# SERDES_10G0 register map
Vendor: Texas Instruments
Registers are 32-bit, access per field, reset 0x0 unless marked. A register's access mark holds for its fields unless they carry their own. Offsets are as the file gives them; [hi:lo] are bit positions; {n}, {i} and the like mark numbered series.

## SERDES_10G0 (part 2 of 8)
0x00 CMN_PID_TYPE ro reset 0x7364 — Product type ID register
  [15:0] CMN_PID_TYPE_15_0 — Product type : This field contains the ASCII codes that represent the product type sd for SerDes.
0x04 CMN_PID_NUM ro reset 0x8010000 — Product number ID register
  [31:16] CMN_PID_NUM_15_0 — Product number : This field contains the binary coded decimal numbers that represent the product number.
0x08 CMN_PID_REV ro reset 0x120 — Product revision ID register
  [15:0] CMN_PID_REV_15_0 — Product revision : This field contains the binary coded decimal numbers that represent the product revision.
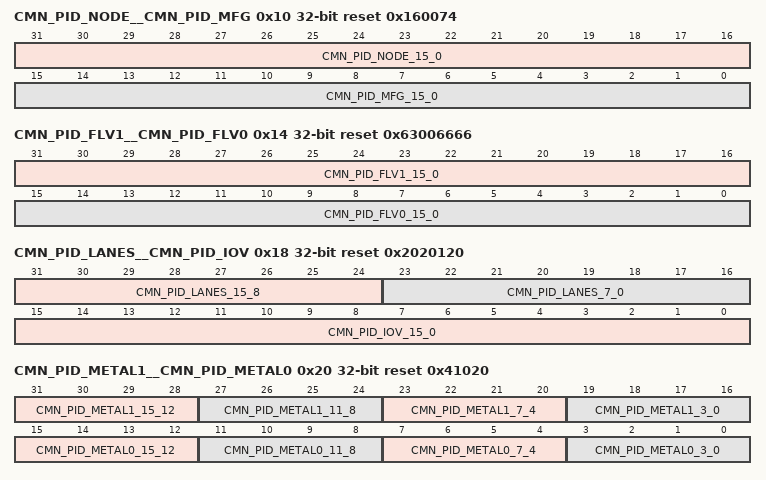
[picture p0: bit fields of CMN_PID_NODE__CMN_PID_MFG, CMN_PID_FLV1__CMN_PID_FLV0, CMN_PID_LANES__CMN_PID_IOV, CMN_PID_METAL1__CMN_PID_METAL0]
0x10 CMN_PID_NODE__CMN_PID_MFG ro reset 0x160074 — Product technology manufacturer ID register
  [31:16] CMN_PID_NODE_15_0 — Product technology process node : This field contains the binary coded decimal numbers that represent the product technology node
  [15:0] CMN_PID_MFG_15_0 — Product technology manufacturer : This field contains the ASCII codes that represent the product technology manufacturer t for TSMC.
0x14 CMN_PID_FLV1__CMN_PID_FLV0 ro reset 0x63006666 — Product technology process flavor ID register 0
  [31:16] CMN_PID_FLV1_15_0 — Product technology flavor : This field contains the ASCII codes that represent the second two characters of the product technology flavor.
  [15:0] CMN_PID_FLV0_15_0 — Product technology flavor : This field contains the ASCII codes that represent the first two characters of the product technology flavor.
0x18 CMN_PID_LANES__CMN_PID_IOV ro reset 0x2020120 — Product I/O voltage ID register
  [31:24] CMN_PID_LANES_15_8 — Product SerDes lanes left of common : This field contains the binary coded decimal numbers that represent the number of lanes implemented in this SerDes product on the left side of the common module.
  [23:16] CMN_PID_LANES_7_0 — Product SerDes lanes right of common : This field contains the binary coded decimal numbers that represent the number of lanes implemented in this SerDes product on the right side of the common module.
  [15:0] CMN_PID_IOV_15_0 — Product I/O voltage : This field contains the binary coded decimal numbers that represent the product I/O voltage.
0x20 CMN_PID_METAL1__CMN_PID_METAL0 ro reset 0x41020 — Product metal layers ID register 0
  [31:28] CMN_PID_METAL1_15_12 — Reserved
  [27:24] CMN_PID_METAL1_11_8 — Reserved
  [23:20] CMN_PID_METAL1_7_4 — Product xy metal layers : This field contains the binary coded decimal number that represent the number of xy metal layers used for this product.
  [19:16] CMN_PID_METAL1_3_0 — Product xe metal layers : This field contains the binary coded decimal number that represent the number of xe metal layers used for this product.
  [15:12] CMN_PID_METAL0_15_12 — Product xd metal layers : This field contains the binary coded decimal number that represent the number of xd metal layers used for this product.
  [11:8] CMN_PID_METAL0_11_8 — Product xc metal layers : This field contains the binary coded decimal number that represent the number of xc metal layers used for this product.
  [7:4] CMN_PID_METAL0_7_4 — Product xa metal layers : This field contains the binary coded decimal number that represent the number of xa metal layers used for this product.
  [3:0] CMN_PID_METAL0_3_0 — Product x metal layers : This field contains the binary coded decimal number that represent the number of x metal layers used for this product.
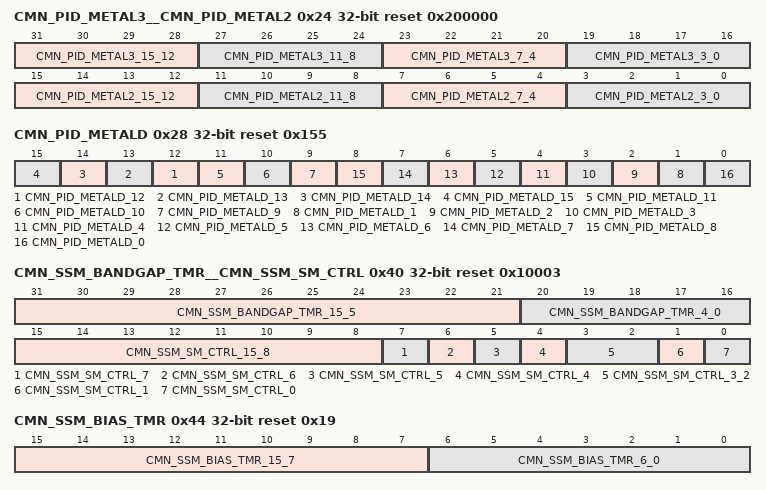
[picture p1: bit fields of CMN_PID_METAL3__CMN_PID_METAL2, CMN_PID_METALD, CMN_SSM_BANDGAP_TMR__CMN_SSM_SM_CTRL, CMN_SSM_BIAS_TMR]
0x24 CMN_PID_METAL3__CMN_PID_METAL2 ro reset 0x200000 — Product metal layers ID register 2
  [31:28] CMN_PID_METAL3_15_12 — Product yz metal layers : This field contains the binary coded decimal number that represent the number of yz metal layers used for this product.
  [27:24] CMN_PID_METAL3_11_8 — Product u metal layers : This field contains the binary coded decimal number that represent the number of u metal layers used for this product.
  [23:20] CMN_PID_METAL3_7_4 — Product r metal layers : This field contains the binary coded decimal number that represent the number of r metal layers used for this product.
  [19:16] CMN_PID_METAL3_3_0 — Product z metal layers : This field contains the binary coded decimal number that represent the number of z metal layers used for this product.
  [15:12] CMN_PID_METAL2_15_12 — Product yz metal layers : This field contains the binary coded decimal number that represent the number of yz metal layers used for this product.
  [11:8] CMN_PID_METAL2_11_8 — Product yy metal layers : This field contains the binary coded decimal number that represent the number of yy metal layers used for this product.
  [7:4] CMN_PID_METAL2_7_4 — Product ya metal layers : This field contains the binary coded decimal number that represent the number of ya metal layers used for this product.
  [3:0] CMN_PID_METAL2_3_0 — Product y metal layers : This field contains the binary coded decimal number that represent the number of y metal layers used for this product.
0x28 CMN_PID_METALD ro reset 0x155 — Product metal layer direction ID register
  [n] CMN_PID_METALD_{n} (n=12..15) — Reserved
  [11] CMN_PID_METALD_11 — Metal 11 direction (when used) :
  [10] CMN_PID_METALD_10 — Metal 10 direction (when used) :
  [9] CMN_PID_METALD_9 — Metal 9 direction (when used) :
  [n] CMN_PID_METALD_{n} (n=1..8) — Metal {n} direction :
  [0] CMN_PID_METALD_0 — Metal 0 direction : This layer does not have a direction associated with it.
0x40 CMN_SSM_BANDGAP_TMR__CMN_SSM_SM_CTRL reset 0x10003 — Startup state machine control register
  [31:21] CMN_SSM_BANDGAP_TMR_15_5 ro — Reserved
  [20:16] CMN_SSM_BANDGAP_TMR_4_0 rw — Bandgap enable state timer value : Value used for the timer when the startup state machine is in the bandgap enable state.
  [15:8] CMN_SSM_SM_CTRL_15_8 ro — Reserved
  [7] CMN_SSM_SM_CTRL_7 rw — Bandgap enable override enable : When active (1'b1), the bandgap enable override bit in this register will drive the ssmda_bandgap_en pin from the SSM directly.
  [6] CMN_SSM_SM_CTRL_6 rw — Bandgap enable override : When enabled by the bandgap enable override enable bit in this register, this bit will drive the ssmda_bandgap_en pin from the SSM directly.
  [5] CMN_SSM_SM_CTRL_5 rw — Bias enable override enable : When active (1'b1), the bias enable override bit in this register will drive the ssmda_bias_en pin from the SSM directly.
  [4] CMN_SSM_SM_CTRL_4 rw — Bias enable override : When enabled by the bias enable override enable bit in this register, this bit will drive the ssmda_bias_en pin from the SSM directly.
  [3:2] CMN_SSM_SM_CTRL_3_2 ro — Reserved
  [1] CMN_SSM_SM_CTRL_1 rw — Skip post bandgap enable re-calibration : When this bit is active (1'b1), the post bandgap enable calibration state will be skipped if it was previously run, unless the macro is disabled or reset.
  [0] CMN_SSM_SM_CTRL_0 rw — Skip auto re-calibration : When this bit is active (1'b1), the auto calibration state will be skipped if it was previously run, unless the macro is disabled or reset.
0x44 CMN_SSM_BIAS_TMR reset 0x19 — Bias enable timer register
  [15:7] CMN_SSM_BIAS_TMR_15_7 ro — Reserved
  [6:0] CMN_SSM_BIAS_TMR_6_0 rw — Bias enable state timer value : Value used for the timer when the startup state machine is in the bias enable state.
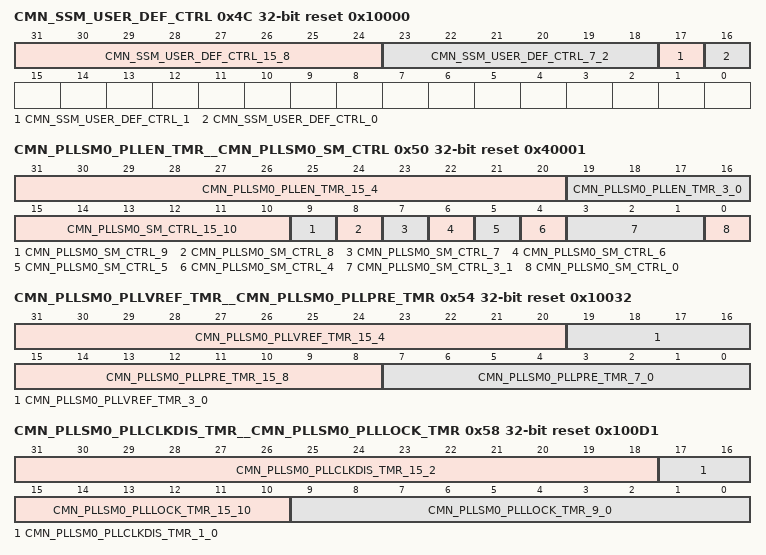
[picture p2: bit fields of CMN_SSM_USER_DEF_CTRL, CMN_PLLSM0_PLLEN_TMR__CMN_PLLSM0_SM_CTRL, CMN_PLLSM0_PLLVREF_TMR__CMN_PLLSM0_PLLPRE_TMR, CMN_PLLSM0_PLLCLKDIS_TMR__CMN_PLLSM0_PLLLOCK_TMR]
0x4C CMN_SSM_USER_DEF_CTRL reset 0x10000 — Startup state machine user defined control register
  [31:24] CMN_SSM_USER_DEF_CTRL_15_8 ro — Reserved
  [23:18] CMN_SSM_USER_DEF_CTRL_7_2 rw — Reserved - spare
  [17] CMN_SSM_USER_DEF_CTRL_1 rw — Force SSM gated clock on: Setting this bit to 1'b1 will force the SSM gated clock on, independent of the internal SSM state machine clock gate controls.
  [16] CMN_SSM_USER_DEF_CTRL_0 rw — Bandgap enable hold enable: This bit enables the bandgap enable hold function, which holds the bandgap enable active in the common suspend state until the signal detect function is switched off.
0x50 CMN_PLLSM0_PLLEN_TMR__CMN_PLLSM0_SM_CTRL reset 0x40001 — PLL 0 control state machine control register
  [31:20] CMN_PLLSM0_PLLEN_TMR_15_4 ro — Reserved
  [19:16] CMN_PLLSM0_PLLEN_TMR_3_0 rw — PLL enable state timer value : Value used for the timer when the startup state machine is in the PLL enable state.
  [15:10] CMN_PLLSM0_SM_CTRL_15_10 ro — Reserved
  [9] CMN_PLLSM0_SM_CTRL_9 rw — PLL enable override enable : When active (1'b1), the PLL enable override bit in this register will drive the pllsmda_pll_en pin from the PLLSM directly.
  [8] CMN_PLLSM0_SM_CTRL_8 rw — PLL enable override : When enabled by the PLL enable override enable bit in this register, this bit will drive the pllsmda_pll_en pin from the PLLSM directly.
  [7] CMN_PLLSM0_SM_CTRL_7 rw — PLL reset override enable : When active (1'b1), the PLL reset override bit in this register will drive the
  [6] CMN_PLLSM0_SM_CTRL_6 rw — PLL reset override : When enabled by the PLL reset override enable bit in this register, this bit will drive the pllsmda_pll_rst_n pin from the PLLSM directly.
  [5] CMN_PLLSM0_SM_CTRL_5 rw — PLL pre charge override enable : When active (1'b1), the PLL pre charge override bit in this register will drive the pllsmda_pll_pre_charge pin from the PLLSM directly.
  [4] CMN_PLLSM0_SM_CTRL_4 rw — PLL pre charge override : When enabled by the PLL pre charge override enable bit in this register, this bit will drive the pllsmda_pll_pre_charge pin from the PLLSM directly.
  [3:1] CMN_PLLSM0_SM_CTRL_3_1 ro — Reserved
  [0] CMN_PLLSM0_SM_CTRL_0 rw — Skip PLL re-calibration : When this bit is active (1'b1), the PLL calibration state will be skipped if it was previously run, unless the PLL is disabled or resetting the state machine.
0x54 CMN_PLLSM0_PLLVREF_TMR__CMN_PLLSM0_PLLPRE_TMR reset 0x10032 — PLL 0 pre-charge timer register
  [31:20] CMN_PLLSM0_PLLVREF_TMR_15_4 ro — Reserved
  [19:16] CMN_PLLSM0_PLLVREF_TMR_3_0 rw — PLL VREF delay state timer value : Value used for the timer when the startup state machine is in the PLL VREF delay state.
  [15:8] CMN_PLLSM0_PLLPRE_TMR_15_8 ro — Reserved
  [7:0] CMN_PLLSM0_PLLPRE_TMR_7_0 rw — PLL pre-charge state timer value : Value used for the timer when the startup state machine is in the PLL pre-charge state.
0x58 CMN_PLLSM0_PLLCLKDIS_TMR__CMN_PLLSM0_PLLLOCK_TMR reset 0x100D1 — PLL 0 lock delay timer register
  [31:18] CMN_PLLSM0_PLLCLKDIS_TMR_15_2 ro — Reserved
  [17:16] CMN_PLLSM0_PLLCLKDIS_TMR_1_0 rw — PLL clock disable delay state timer value : Value used for the timer when the startup state machine is in the PLL clock disable delay state.
  [15:10] CMN_PLLSM0_PLLLOCK_TMR_15_10 ro — Reserved
  [9:0] CMN_PLLSM0_PLLLOCK_TMR_9_0 rw — PLL lock delay state timer value : Value used for the timer when the startup state machine is in the PLL lock delay state.
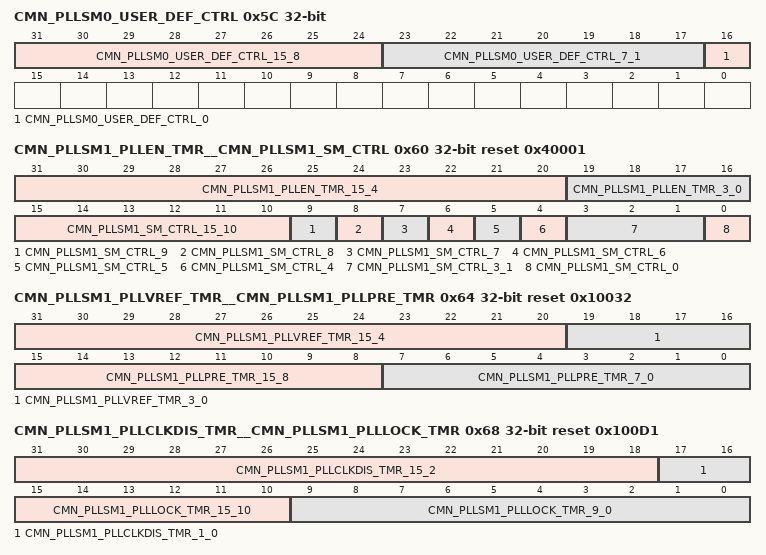
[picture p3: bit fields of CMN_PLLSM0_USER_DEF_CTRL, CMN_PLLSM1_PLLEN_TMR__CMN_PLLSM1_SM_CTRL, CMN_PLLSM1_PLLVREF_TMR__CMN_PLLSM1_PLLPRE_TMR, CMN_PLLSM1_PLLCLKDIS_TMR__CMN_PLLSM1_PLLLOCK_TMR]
0x5C CMN_PLLSM0_USER_DEF_CTRL — PLL 0 control state machine user defined control register
  [31:24] CMN_PLLSM0_USER_DEF_CTRL_15_8 ro — Reserved
  [23:17] CMN_PLLSM0_USER_DEF_CTRL_7_1 rw — Reserved - spare
  [16] CMN_PLLSM0_USER_DEF_CTRL_0 rw — PLL lock override: When active (1'b1), this bit will force the PLL lock indication active.
0x60 CMN_PLLSM1_PLLEN_TMR__CMN_PLLSM1_SM_CTRL reset 0x40001 — PLL 1 control state machine control register
  [31:20] CMN_PLLSM1_PLLEN_TMR_15_4 ro — Reserved
  [19:16] CMN_PLLSM1_PLLEN_TMR_3_0 rw — PLL enable state timer value : Value used for the timer when the startup state machine is in the PLL enable state.
  [15:10] CMN_PLLSM1_SM_CTRL_15_10 ro — Reserved
  [9] CMN_PLLSM1_SM_CTRL_9 rw — PLL enable override enable : When active (1'b1), the PLL enable override bit in this register will drive the pllsmda_pll_en pin from the PLLSM directly.
  [8] CMN_PLLSM1_SM_CTRL_8 rw — PLL enable override : When enabled by the PLL enable override enable bit in this register, this bit will drive the pllsmda_pll_en pin from the PLLSM directly.
  [7] CMN_PLLSM1_SM_CTRL_7 rw — PLL reset override enable : When active (1'b1), the PLL reset override bit in this register will drive the
  [6] CMN_PLLSM1_SM_CTRL_6 rw — PLL reset override : When enabled by the PLL reset override enable bit in this register, this bit will drive the pllsmda_pll_rst_n pin from the PLLSM directly.
  [5] CMN_PLLSM1_SM_CTRL_5 rw — PLL pre charge override enable : When active (1'b1), the PLL pre charge override bit in this register will drive the pllsmda_pll_pre_charge pin from the PLLSM directly.
  [4] CMN_PLLSM1_SM_CTRL_4 rw — PLL pre charge override : When enabled by the PLL pre charge override enable bit in this register, this bit will drive the pllsmda_pll_pre_charge pin from the PLLSM directly.
  [3:1] CMN_PLLSM1_SM_CTRL_3_1 ro — Reserved
  [0] CMN_PLLSM1_SM_CTRL_0 rw — Skip PLL re-calibration : When this bit is active (1'b1), the PLL calibration state will be skipped if it was previously run, unless the PLL is disabled or resetting the state machine.
0x64 CMN_PLLSM1_PLLVREF_TMR__CMN_PLLSM1_PLLPRE_TMR reset 0x10032 — PLL 1 pre-charge timer register
  [31:20] CMN_PLLSM1_PLLVREF_TMR_15_4 ro — Reserved
  [19:16] CMN_PLLSM1_PLLVREF_TMR_3_0 rw — PLL VREF delay state timer value : Value used for the timer when the startup state machine is in the PLL VREF delay state.
  [15:8] CMN_PLLSM1_PLLPRE_TMR_15_8 ro — Reserved
  [7:0] CMN_PLLSM1_PLLPRE_TMR_7_0 rw — PLL pre-charge state timer value : Value used for the timer when the startup state machine is in the PLL pre-charge state.
0x68 CMN_PLLSM1_PLLCLKDIS_TMR__CMN_PLLSM1_PLLLOCK_TMR reset 0x100D1 — PLL 1 lock delay timer register
  [31:18] CMN_PLLSM1_PLLCLKDIS_TMR_15_2 ro — Reserved
  [17:16] CMN_PLLSM1_PLLCLKDIS_TMR_1_0 rw — PLL clock disable delay state timer value : Value used for the timer when the startup state machine is in the PLL clock disable delay state.
  [15:10] CMN_PLLSM1_PLLLOCK_TMR_15_10 ro — Reserved
  [9:0] CMN_PLLSM1_PLLLOCK_TMR_9_0 rw — PLL lock delay state timer value : Value used for the timer when the startup state machine is in the PLL lock delay state.
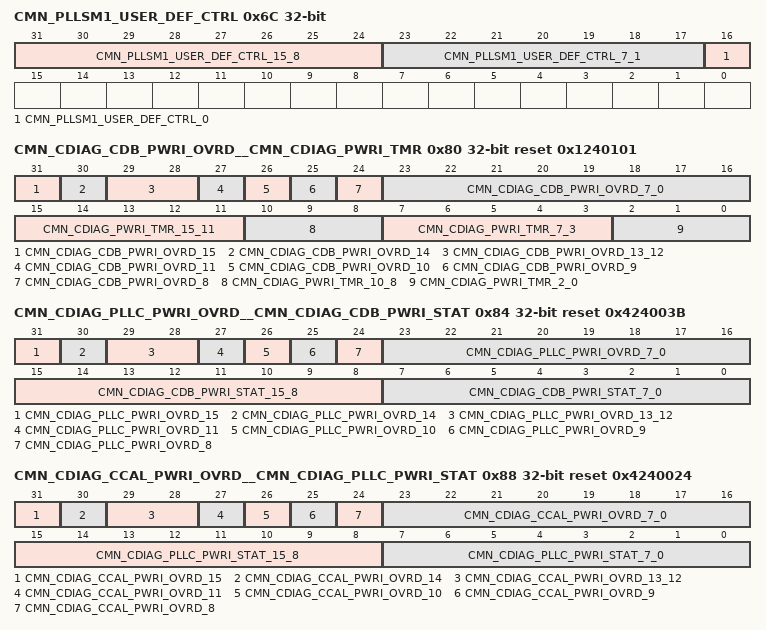
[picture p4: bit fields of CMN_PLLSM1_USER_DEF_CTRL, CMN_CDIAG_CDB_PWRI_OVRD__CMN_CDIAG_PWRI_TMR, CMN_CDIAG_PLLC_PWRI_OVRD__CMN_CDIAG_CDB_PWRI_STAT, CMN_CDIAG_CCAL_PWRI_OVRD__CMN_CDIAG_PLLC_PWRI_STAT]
0x6C CMN_PLLSM1_USER_DEF_CTRL — PLL 1 control state machine user defined control register
  [31:24] CMN_PLLSM1_USER_DEF_CTRL_15_8 ro — Reserved
  [23:17] CMN_PLLSM1_USER_DEF_CTRL_7_1 rw — Reserved - spare
  [16] CMN_PLLSM1_USER_DEF_CTRL_0 rw — PLL lock override: When active (1'b1), this bit will force the PLL lock indication active.
0x80 CMN_CDIAG_CDB_PWRI_OVRD__CMN_CDIAG_PWRI_TMR reset 0x1240101 — Common power island control timer register
  [31] CMN_CDIAG_CDB_PWRI_OVRD_15 rw — Power island controller input override enable: When enabled, the power island control state machine input override bits in this register will drive the power island control state machine directly, and override any control from other state machines in the macro.
  [30] CMN_CDIAG_CDB_PWRI_OVRD_14 rw — Power island controller output override enable: When enabled, the power island control state machine output override bits in this register will drive the power island control state machine outputs, and override any control from power island control state machine.
  [29:28] CMN_CDIAG_CDB_PWRI_OVRD_13_12 ro — Reserved
  [27] CMN_CDIAG_CDB_PWRI_OVRD_11 rw — Power suspend request override: When enabled, this bit will override the power_suspend_req input of the power island control state machine.
  [26] CMN_CDIAG_CDB_PWRI_OVRD_10 ro — Power suspend acknowledge: This is the current state of the power_suspend_ack output from the power island control state machine.
  [25] CMN_CDIAG_CDB_PWRI_OVRD_9 rw — Power recover request override: When enabled, this bit will override the power_recover_req input of the power island control state machine.
  [24] CMN_CDIAG_CDB_PWRI_OVRD_8 ro — Power recover acknowledge: This is the current state of the power_recover_ack output from the power island control state machine.
  [23:16] CMN_CDIAG_CDB_PWRI_OVRD_7_0 rw — Power island controller output override: When enabled, the bits in this field will override the output signals from the power island control state machine.
  [15:11] CMN_CDIAG_PWRI_TMR_15_11 ro — Reserved
  [10:8] CMN_CDIAG_PWRI_TMR_10_8 rw — Power enable phase 2 timer value: This specifies the number of reference clock cycles the power island control state machines in common will wait in the power phase 2 enable states, in order to allow enough time for the second phase of the switched domain to power up, before deactivating the isolation functions.
  [7:3] CMN_CDIAG_PWRI_TMR_7_3 ro — Reserved
  [2:0] CMN_CDIAG_PWRI_TMR_2_0 rw — Power enable phase 1 timer value: This specifies the number of reference clock cycles the power island control state machines in common will wait in the power phase 1 enable states, in order to allow enough time for the first phase of the switched domain to power up, before enabling the second phase of the power up.
0x84 CMN_CDIAG_PLLC_PWRI_OVRD__CMN_CDIAG_CDB_PWRI_STAT reset 0x424003B — Common CDB power island control status register
  [31] CMN_CDIAG_PLLC_PWRI_OVRD_15 rw — Power island controller input override enable: When enabled, the power island control state machine input override bits in this register will drive the power island control state machine directly, and override any control from other state machines in the macro.
  [30] CMN_CDIAG_PLLC_PWRI_OVRD_14 rw — Power island controller output override enable: When enabled, the power island control state machine output override bits in this register will drive the power island control state machine outputs, and override any control from power island control state machine.
  [29:28] CMN_CDIAG_PLLC_PWRI_OVRD_13_12 ro — Reserved
  [27] CMN_CDIAG_PLLC_PWRI_OVRD_11 rw — Power suspend request override: When enabled, this bit will override the power_suspend_req input of the power island control state machine.
  [26] CMN_CDIAG_PLLC_PWRI_OVRD_10 ro — Power suspend acknowledge: This is the current state of the power_suspend_ack output from the power island control state machine.
  [25] CMN_CDIAG_PLLC_PWRI_OVRD_9 rw — Power recover request override: When enabled, this bit will override the power_recover_req input of the power island control state machine.
  [24] CMN_CDIAG_PLLC_PWRI_OVRD_8 ro — Power recover acknowledge: This is the current state of the power_recover_ack output from the power island control state machine.
  [23:16] CMN_CDIAG_PLLC_PWRI_OVRD_7_0 rw — Power island controller output override: When enabled, the bits in this field will override the output signals from the power island control state machine.
  [15:8] CMN_CDIAG_CDB_PWRI_STAT_15_8 ro — Reserved
  [7:0] CMN_CDIAG_CDB_PWRI_STAT_7_0 ro — Power island controller output status: This field indicates the current state of the output signals from the power island control state machine.
0x88 CMN_CDIAG_CCAL_PWRI_OVRD__CMN_CDIAG_PLLC_PWRI_STAT reset 0x4240024 — Common PLL controller power island control status register
  [31] CMN_CDIAG_CCAL_PWRI_OVRD_15 rw — Power island controller input override enable: When enabled, the power island control state machine input override bits in this register will drive the power island control state machine directly, and override any control from other state machines in the macro.
  [30] CMN_CDIAG_CCAL_PWRI_OVRD_14 rw — Power island controller output override enable: When enabled, the power island control state machine output override bits in this register will drive the power island control state machine outputs, and override any control from power island control state machine.
  [29:28] CMN_CDIAG_CCAL_PWRI_OVRD_13_12 ro — Reserved
  [27] CMN_CDIAG_CCAL_PWRI_OVRD_11 rw — Power suspend request override: When enabled, this bit will override the power_suspend_req input of the power island control state machine.
  [26] CMN_CDIAG_CCAL_PWRI_OVRD_10 ro — Power suspend acknowledge: This is the current state of the power_suspend_ack output from the power island control state machine.
  [25] CMN_CDIAG_CCAL_PWRI_OVRD_9 rw — Power recover request override: When enabled, this bit will override the power_recover_req input of the power island control state machine.
  [24] CMN_CDIAG_CCAL_PWRI_OVRD_8 ro — Power recover acknowledge: This is the current state of the power_recover_ack output from the power island control state machine.
  [23:16] CMN_CDIAG_CCAL_PWRI_OVRD_7_0 rw — Power island controller output override: When enabled, the bits in this field will override the output signals from the power island control state machine.
  [15:8] CMN_CDIAG_PLLC_PWRI_STAT_15_8 ro — Reserved
  [7:0] CMN_CDIAG_PLLC_PWRI_STAT_7_0 ro — Power island controller output status: This field indicates the current state of the output signals from the power island control state machine.
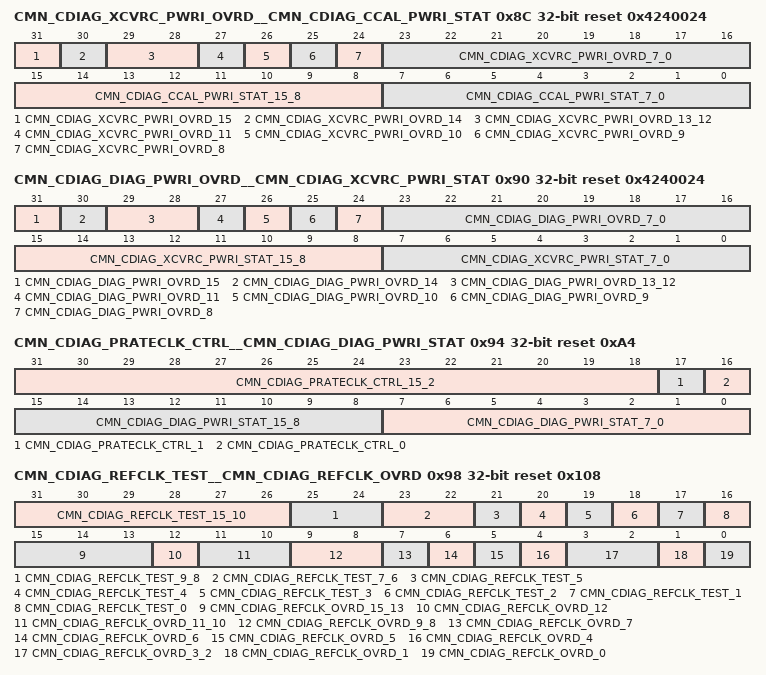
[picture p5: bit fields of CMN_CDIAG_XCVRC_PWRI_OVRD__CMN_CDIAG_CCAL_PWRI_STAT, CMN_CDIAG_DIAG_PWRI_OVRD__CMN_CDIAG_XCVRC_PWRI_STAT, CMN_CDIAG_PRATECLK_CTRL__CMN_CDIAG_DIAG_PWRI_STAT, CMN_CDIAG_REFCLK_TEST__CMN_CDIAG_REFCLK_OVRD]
0x8C CMN_CDIAG_XCVRC_PWRI_OVRD__CMN_CDIAG_CCAL_PWRI_STAT reset 0x4240024 — Common common calibration power island control status register
  [31] CMN_CDIAG_XCVRC_PWRI_OVRD_15 rw — Power island controller input override enable: When enabled, the power island control state machine input override bits in this register will drive the power island control state machine directly, and override any control from other state machines in the macro.
  [30] CMN_CDIAG_XCVRC_PWRI_OVRD_14 rw — Power island controller output override enable: When enabled, the power island control state machine output override bits in this register will drive the power island control state machine outputs, and override any control from power island control state machine.
  [29:28] CMN_CDIAG_XCVRC_PWRI_OVRD_13_12 ro — Reserved
  [27] CMN_CDIAG_XCVRC_PWRI_OVRD_11 rw — Power suspend request override: When enabled, this bit will override the power_suspend_req input of the power island control state machine.
  [26] CMN_CDIAG_XCVRC_PWRI_OVRD_10 ro — Power suspend acknowledge: This is the current state of the power_suspend_ack output from the power island control state machine.
  [25] CMN_CDIAG_XCVRC_PWRI_OVRD_9 rw — Power recover request override: When enabled, this bit will override the power_recover_req input of the power island control state machine.
  [24] CMN_CDIAG_XCVRC_PWRI_OVRD_8 ro — Power recover acknowledge: This is the current state of the power_recover_ack output from the power island control state machine.
  [23:16] CMN_CDIAG_XCVRC_PWRI_OVRD_7_0 rw — Power island controller output override: When enabled, the bits in this field will override the output signals from the power island control state machine.
  [15:8] CMN_CDIAG_CCAL_PWRI_STAT_15_8 ro — Reserved
  [7:0] CMN_CDIAG_CCAL_PWRI_STAT_7_0 ro — Power island controller output status: This field indicates the current state of the output signals from the power island control state machine.
0x90 CMN_CDIAG_DIAG_PWRI_OVRD__CMN_CDIAG_XCVRC_PWRI_STAT reset 0x4240024 — Common transceiver controller power island control status register
  [31] CMN_CDIAG_DIAG_PWRI_OVRD_15 rw — Power island controller input override enable: When enabled, the power island control state machine input override bits in this register will drive the power island control state machine directly, and override any control from other state machines in the macro.
  [30] CMN_CDIAG_DIAG_PWRI_OVRD_14 rw — Power island controller output override enable: When enabled, the power island control state machine output override bits in this register will drive the power island control state machine outputs, and override any control from power island control state machine.
  [29:28] CMN_CDIAG_DIAG_PWRI_OVRD_13_12 ro — Reserved
  [27] CMN_CDIAG_DIAG_PWRI_OVRD_11 rw — Power suspend request override: When enabled, this bit will override the power_suspend_req input of the power island control state machine.
  [26] CMN_CDIAG_DIAG_PWRI_OVRD_10 ro — Power suspend acknowledge: This is the current state of the power_suspend_ack output from the power island control state machine.
  [25] CMN_CDIAG_DIAG_PWRI_OVRD_9 rw — Power recover request override: When enabled, this bit will override the power_recover_req input of the power island control state machine.
  [24] CMN_CDIAG_DIAG_PWRI_OVRD_8 ro — Power recover acknowledge: This is the current state of the power_recover_ack output from the power island control state machine.
  [23:16] CMN_CDIAG_DIAG_PWRI_OVRD_7_0 rw — Power island controller output override: When enabled, the bits in this field will override the output signals from the power island control state machine.
  [15:8] CMN_CDIAG_XCVRC_PWRI_STAT_15_8 ro — Reserved
  [7:0] CMN_CDIAG_XCVRC_PWRI_STAT_7_0 ro — Power island controller output status: This field indicates the current state of the output signals from the power island control state machine.
0x94 CMN_CDIAG_PRATECLK_CTRL__CMN_CDIAG_DIAG_PWRI_STAT reset 0xA4 — Common diagnostic power island control status register
  [31:18] CMN_CDIAG_PRATECLK_CTRL_15_2 ro — Reserved
  [17] CMN_CDIAG_PRATECLK_CTRL_1 rw — Common PLL 1 full rate and data rate source clock select: Selects the PLL source clock to use when generating the cmn_pll1_clk_fullrt, cmn_pll1_clk_datart0, and cmn_pll1_clk_datart1 clocks.
  [16] CMN_CDIAG_PRATECLK_CTRL_0 rw — Common PLL 0 full rate and data rate source clock select: Selects the PLL source clock to use when generating the cmn_pll0_clk_fullrt, cmn_pll0_clk_datart0, and cmn_pll0_clk_datart1 clocks.
  [15:8] CMN_CDIAG_DIAG_PWRI_STAT_15_8 ro — Reserved
  [7:0] CMN_CDIAG_DIAG_PWRI_STAT_7_0 ro — Power island controller output status: This field indicates the current state of the output signals from the power island control state machine.
0x98 CMN_CDIAG_REFCLK_TEST__CMN_CDIAG_REFCLK_OVRD reset 0x108 — Reference clock receiver override register
  [31:26] CMN_CDIAG_REFCLK_TEST_15_10 ro — Reserved
  [25:24] CMN_CDIAG_REFCLK_TEST_9_8 rw — Reserved - spare
  [23:22] CMN_CDIAG_REFCLK_TEST_7_6 ro — Reserved
  [21] CMN_CDIAG_REFCLK_TEST_5 rw — Reference clock driver 0 test mode enable: Enables the reference clock driver DC test mode, by controlling the cmnda_ref_clk0_drv_test_en signal going into the analog.
  [20] CMN_CDIAG_REFCLK_TEST_4 rw — Reference clock driver 0 test mode value: When enabled by the reference clock driver 0 test mode enable bit in this register, the value in this bit will be driven by the reference clock driver, by controlling the cmnda_ref_clk0_drv_test_val signal going into the analog.
  [19] CMN_CDIAG_REFCLK_TEST_3 ro — Reserved
  [18] CMN_CDIAG_REFCLK_TEST_2 rw — Reference clock receiver test mode enable: Enables the reference clock receiver DC test mode, by controlling the cmnda_ref_clk_rcv_test_en signal going into the analog.
  [17] CMN_CDIAG_REFCLK_TEST_1 ro — Reference clock receiver test mode PLL value: When enabled by the reference clock receiver test mode enable bit in this register, the value in this bit will be the value present on the PLL reference clock receiver.
  [16] CMN_CDIAG_REFCLK_TEST_0 ro — Reference clock receiver test mode digital value: When enabled by the reference clock receiver test mode enable bit in this register, the value in this bit will be the value present on the digital reference clock receiver.
  [15:13] CMN_CDIAG_REFCLK_OVRD_15_13 ro — Reserved
  [12] CMN_CDIAG_REFCLK_OVRD_12 rw — Derived reference clock source select: Selects which PLL is the source for the derived reference clock, by driving the cmnda_ref_clk_der_src_sel signal to the analog.
  [11:10] CMN_CDIAG_REFCLK_OVRD_11_10 ro — Reserved
  [9:8] CMN_CDIAG_REFCLK_OVRD_9_8 rw — Digital reference clock receiver hysteresis adjust: Control the amount of hysteresis used for the digital reference clock receiver, by driving the cmnda_ref_clk_dig_hyst_adj signal to the analog.
  [7] CMN_CDIAG_REFCLK_OVRD_7 ro — Reserved
  [6] CMN_CDIAG_REFCLK_OVRD_6 rw — Analog reference clock enable override: This bit can be used to force the cmnda_ref_clk_en signal going to the analog to the active state.
  [5] CMN_CDIAG_REFCLK_OVRD_5 rw — Reference clock AC coupling cap bypass: Controls the bypassing of the AC coupling caps in the differential receiver.
  [4] CMN_CDIAG_REFCLK_OVRD_4 rw — Derived reference clock enable: Enables the derived reference clock function, by driving the cmnda_ref_clk_der_en signal to the analog.
  [3:2] CMN_CDIAG_REFCLK_OVRD_3_2 rw — Reference clock high pass filter control: Controls the cutoff frequency of the high pass filter in the reference clock receiver input.
  [1] CMN_CDIAG_REFCLK_OVRD_1 ro — Reserved
  [0] CMN_CDIAG_REFCLK_OVRD_0 rw — Reference clock receiver circuit clock control:
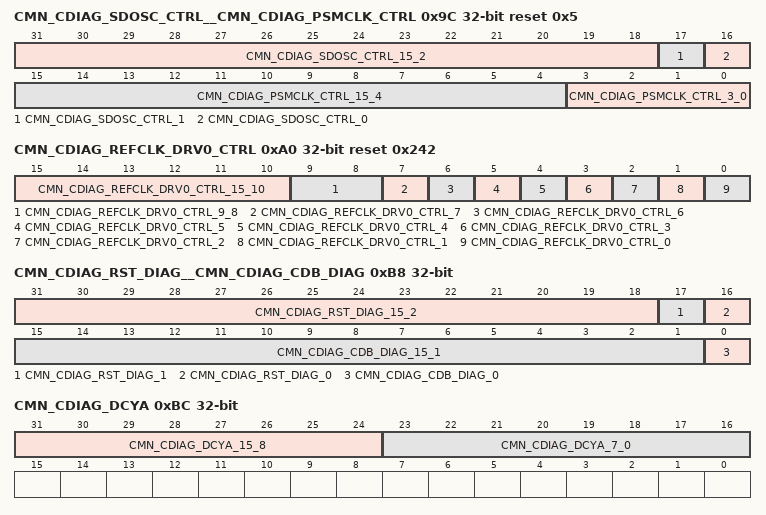
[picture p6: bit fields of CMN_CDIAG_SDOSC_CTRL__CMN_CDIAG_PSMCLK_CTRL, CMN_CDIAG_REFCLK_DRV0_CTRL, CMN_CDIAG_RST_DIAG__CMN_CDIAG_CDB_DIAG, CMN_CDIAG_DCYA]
0x9C CMN_CDIAG_SDOSC_CTRL__CMN_CDIAG_PSMCLK_CTRL reset 0x5 — Power state machine clock receiver control register
  [31:18] CMN_CDIAG_SDOSC_CTRL_15_2 ro — Reserved
  [17] CMN_CDIAG_SDOSC_CTRL_1 rw — Oscillator Enable Override Enable: This bit enables the oscillator enable override bit in this register to directly control the signal detect oscillator.
  [16] CMN_CDIAG_SDOSC_CTRL_0 rw — Oscillator Enable Override: When enabled by the oscillator enable override enable bit in this register, this bit can be used to directly control the enable of the signal detect oscillator.
  [15:4] CMN_CDIAG_PSMCLK_CTRL_15_4 ro — Reserved
  [3:0] CMN_CDIAG_PSMCLK_CTRL_3_0 rw — PSM clock divider value: The value of this field is used to control the divider setting of the PSM clock divider.
0xA0 CMN_CDIAG_REFCLK_DRV0_CTRL reset 0x242 — Reference clock bump driver 0 control register
  [15:10] CMN_CDIAG_REFCLK_DRV0_CTRL_15_10 ro — Reserved
  [9:8] CMN_CDIAG_REFCLK_DRV0_CTRL_9_8 rw — Clock driver drive current tune: Controls the amplitude of the reference clock driver, by controlling the cmnda_ref_clk0_itune signal going to the analog.
  [7] CMN_CDIAG_REFCLK_DRV0_CTRL_7 ro — Reserved
  [6] CMN_CDIAG_REFCLK_DRV0_CTRL_6 rw — Reference clock driver high Z: When the reference clock driver is disabled, this controls if the driver outputs are high Z or pulled low, by controlling the cmnda_ref_clk0_drv_highz signal going to the analog.
  [5] CMN_CDIAG_REFCLK_DRV0_CTRL_5 rw — Clock driver termination: Enables the termination in the reference clock driver, by controlling the cmnda_ref_clk0_termination signal going to the analog.
  [4] CMN_CDIAG_REFCLK_DRV0_CTRL_4 rw — Clock select: Selects which reference clock that will be driven by the reference clock driver, by controlling the cmnda_ref_clk0_clk_select signal going to the analog.
  [3] CMN_CDIAG_REFCLK_DRV0_CTRL_3 rw — Clock gate enable override enable: This bit enables the clock gate enable override bit in this register to override the clock gate of the reference clock driver.
  [2] CMN_CDIAG_REFCLK_DRV0_CTRL_2 rw — Clock gate enable override: When enabled by the clock gate enable override enable bit in this register, this bit can be used to directly control the clock gate enable of the reference clock driver by controlling the cmnda_ref_clk0_clk_gate_en signal going to the analog.
  [1] CMN_CDIAG_REFCLK_DRV0_CTRL_1 rw — Driver enable override enable: This bit enables the driver enable override bit in this register to override the enable of the reference clock driver.
  [0] CMN_CDIAG_REFCLK_DRV0_CTRL_0 rw — Driver enable override: When enabled by the driver enable override enable bit in this register, this bit can be used to directly control the enable of the reference clock driver by controlling the cmnda_ref_clk0_drv_en signal going to the analog.
0xB8 CMN_CDIAG_RST_DIAG__CMN_CDIAG_CDB_DIAG ro — Common control CDB diagnostic register
  [31:18] CMN_CDIAG_RST_DIAG_15_2 — Reserved
  [17] CMN_CDIAG_RST_DIAG_1 — Current state of the cdb_isl_ctrl_sm_reset_n reset.
  [16] CMN_CDIAG_RST_DIAG_0 — Current state of the cmn_reset_sync_n reset.
  [15:1] CMN_CDIAG_CDB_DIAG_15_1 — Reserved
  [0] CMN_CDIAG_CDB_DIAG_0 — CDB bus error: This bit will be set when the internal CDB watchdog timer expires.
0xBC CMN_CDIAG_DCYA — Common control cover your alternatives register
  [31:24] CMN_CDIAG_DCYA_15_8 ro — Reserved
  [23:16] CMN_CDIAG_DCYA_7_0 rw — Reserved - spare
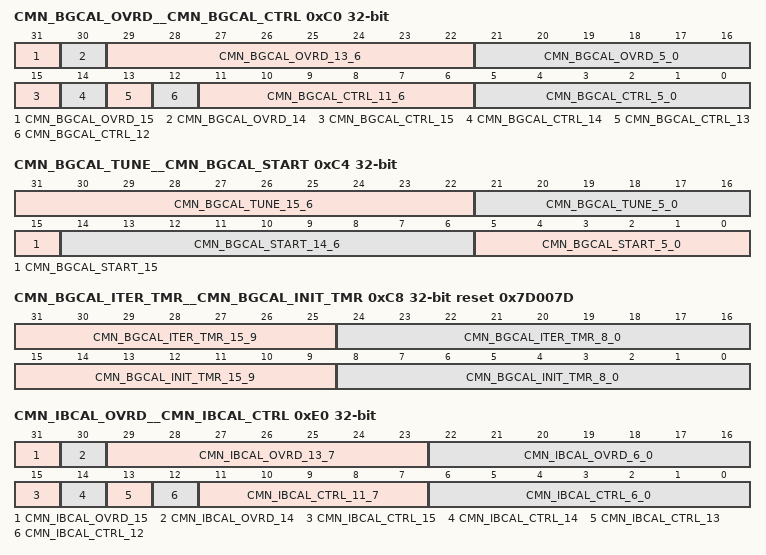
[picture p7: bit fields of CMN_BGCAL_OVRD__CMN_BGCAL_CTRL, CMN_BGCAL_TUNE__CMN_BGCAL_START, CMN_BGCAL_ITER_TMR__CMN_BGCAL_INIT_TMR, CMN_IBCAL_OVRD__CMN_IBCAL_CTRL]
0xC0 CMN_BGCAL_OVRD__CMN_BGCAL_CTRL — Bandgap calibration control register
  [31] CMN_BGCAL_OVRD_15 rw — Bandgap code override enable: Activation (1'b1) of this register bit allows the bandgap codes determined during the automatic calibration process to be overridden.
  [30] CMN_BGCAL_OVRD_14 rw — Analog calibration enable override: Activation (1'b1) of this register bit will force the analog calibration circuits to be enabled by activating the cmnda_bias_bgcal_en enable.
  [29:22] CMN_BGCAL_OVRD_13_6 ro — Reserved
  [21:16] CMN_BGCAL_OVRD_5_0 rw — Bandgap code override value: These bits are used to override the bandgap code determined during the automatic calibration process.
  [15] CMN_BGCAL_CTRL_15 rw — Start bandgap calibration: Activating (1'b1) this bit will start the bandgap calibration process.
  [14] CMN_BGCAL_CTRL_14 ro — Bandgap calibration process done: This bit will be set to 1'b1 when the bandgap calibration process is complete.
  [13] CMN_BGCAL_CTRL_13 ro — No analog calibration response : This signal indicates that the calibration function has gone through the entire calibration process, reached the final calibration value, and the analog has not responded indicating that a valid calibration value has been reached.
  [12] CMN_BGCAL_CTRL_12 ro — Current analog comparator response: This is the current state of the analog comparator response signal (cmnda_bias_bgcal_comp).
  [11:6] CMN_BGCAL_CTRL_11_6 ro — Reserved
  [5:0] CMN_BGCAL_CTRL_5_0 ro — Bandgap calibration code: This is the calibration code that was determined by the bandgap calibration process.
0xC4 CMN_BGCAL_TUNE__CMN_BGCAL_START — Bandgap calibration start register
  [31:22] CMN_BGCAL_TUNE_15_6 ro — Reserved
  [21:16] CMN_BGCAL_TUNE_5_0 rw — Bandgap calibration tune value: The value of this field is added to the automatically calibrated code, or the override code if override is enabled.
  [15] CMN_BGCAL_START_15 rw — Bandgap calibration direction: This controls the direction that the automatic calibration process steps the calibration codes in.
  [14:6] CMN_BGCAL_START_14_6 ro — Reserved
  [5:0] CMN_BGCAL_START_5_0 rw — Start bandgap calibration code: This is the calibration code that the calibration process starts with when automatic calibration is run.
0xC8 CMN_BGCAL_ITER_TMR__CMN_BGCAL_INIT_TMR reset 0x7D007D — Bandgap calibration initialization timer register
  [31:25] CMN_BGCAL_ITER_TMR_15_9 ro — Reserved
  [24:16] CMN_BGCAL_ITER_TMR_8_0 rw — Iteration wait timer value: This is the number of cmn_ref_clk clocks to wait between when a value is placed on the bandgap calibration signals going to the analog, and when the comparator value coming from the analog circuits can be checked.
  [15:9] CMN_BGCAL_INIT_TMR_15_9 ro — Reserved
  [8:0] CMN_BGCAL_INIT_TMR_8_0 rw — Initialization wait timer value: This is the number of cmn_ref_clk clocks to wait between when the analog bandgap calibration circuits are enabled, and when the first values are placed on the bandgap calibration signals going to the analog.
0xE0 CMN_IBCAL_OVRD__CMN_IBCAL_CTRL — External bias current calibration control register
  [31] CMN_IBCAL_OVRD_15 rw — Calibration code override enable: Activation (1'b1) of this register bit allows the calibration code determined during the automatic resistor calibration process to be overridden.
  [30] CMN_IBCAL_OVRD_14 rw — Analog calibration enable override: Activation (1'b1) of this register bit will force the analog calibration circuits to be enabled by activating the cmnda_ibiascal_en enable and the cmnda_ibiascal_clk clock.
  [29:23] CMN_IBCAL_OVRD_13_7 ro — Reserved
  [22:16] CMN_IBCAL_OVRD_6_0 rw — Calibration code override value: These bits are used to override the calibration code determined during the automatic resistor calibration process.
  [15] CMN_IBCAL_CTRL_15 rw — Start calibration: Activating (1'b1) this bit will start the calibration process.
  [14] CMN_IBCAL_CTRL_14 ro — Calibration process done: This bit will be set to 1'b1 when the calibration process is complete.
  [13] CMN_IBCAL_CTRL_13 ro — No analog calibration response : This signal indicates that the calibration function has gone through the entire calibration process, reached the final calibration value, and the analog has not responded indicating that a valid calibration value has been reached.
  [12] CMN_IBCAL_CTRL_12 ro — Current analog comparator response: This is the current state of the analog comparator response signal (cmnda_ibiascal_comp).
  [11:7] CMN_IBCAL_CTRL_11_7 ro — Reserved
  [6:0] CMN_IBCAL_CTRL_6_0 ro — Calibration code: This is the calibration code that was determined by the calibration process.
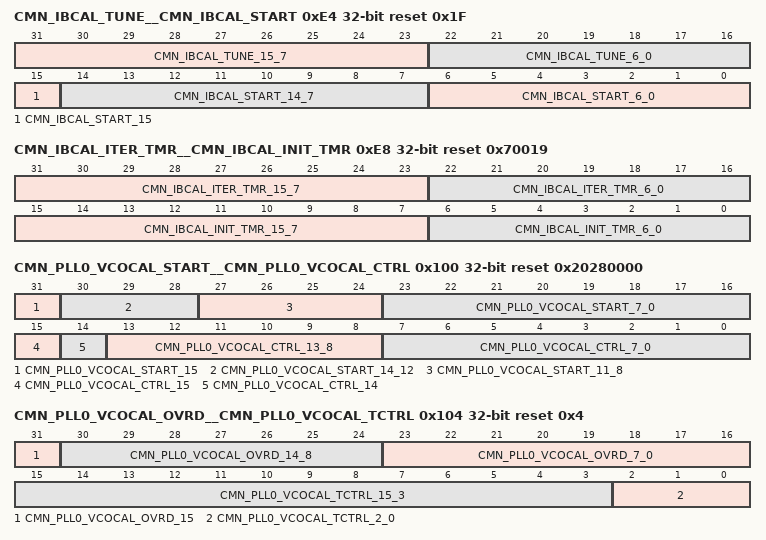
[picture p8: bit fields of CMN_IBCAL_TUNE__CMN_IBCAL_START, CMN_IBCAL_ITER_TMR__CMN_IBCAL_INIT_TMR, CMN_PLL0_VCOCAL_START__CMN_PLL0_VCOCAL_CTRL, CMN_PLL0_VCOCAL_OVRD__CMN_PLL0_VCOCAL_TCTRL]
0xE4 CMN_IBCAL_TUNE__CMN_IBCAL_START reset 0x1F — External bias current calibration start register
  [31:23] CMN_IBCAL_TUNE_15_7 ro — Reserved
  [22:16] CMN_IBCAL_TUNE_6_0 rw — Calibration tune value: The value of this field is added to the automatically calibrated code, or the override code if override is enabled.
  [15] CMN_IBCAL_START_15 rw — Calibration direction: This controls the direction that the automatic calibration process steps the calibration codes in.
  [14:7] CMN_IBCAL_START_14_7 ro — Reserved
  [6:0] CMN_IBCAL_START_6_0 rw — Start resistor calibration code: This is the calibration code that the resistor calibration process starts with when automatic calibration is run.
0xE8 CMN_IBCAL_ITER_TMR__CMN_IBCAL_INIT_TMR reset 0x70019 — External bias current calibration initialization timer register
  [31:23] CMN_IBCAL_ITER_TMR_15_7 ro — Reserved
  [22:16] CMN_IBCAL_ITER_TMR_6_0 rw — Iteration wait timer value: This is the number of cmn_ref_clk clocks to wait between when a value is placed on the calibration selection bus going to the analog, and when the comparator value coming from the analog circuits can be checked.
  [15:7] CMN_IBCAL_INIT_TMR_15_7 ro — Reserved
  [6:0] CMN_IBCAL_INIT_TMR_6_0 rw — Initialization wait timer value: This is the number of cmn_ref_clk clocks to wait between when the analog calibration circuits are enabled, and when the first calibration selection value is placed on the calibration code bus, going to the analog.
0x100 CMN_PLL0_VCOCAL_START__CMN_PLL0_VCOCAL_CTRL reset 0x20280000 — PLL 0 VCO calibration control register
  [31] CMN_PLL0_VCOCAL_START_15 ro — Reserved
  [30:28] CMN_PLL0_VCOCAL_START_14_12 rw — VCO calibration initial step size control: This field specifies the initial step size for the VCO calibration state machine.
  [27:24] CMN_PLL0_VCOCAL_START_11_8 ro — Reserved
  [23:16] CMN_PLL0_VCOCAL_START_7_0 rw — VCO calibration code starting point value: This field specifies the starting VCO code that is used by the VCO calibration state machine.
  [15] CMN_PLL0_VCOCAL_CTRL_15 rw — Start VCO calibration: Activating (1'b1) this bit will start a VCO calibration process.
  [14] CMN_PLL0_VCOCAL_CTRL_14 ro — VCO calibration process done: This bit will be set to 1'b1 when the VCO calibration process is complete.
  [13:8] CMN_PLL0_VCOCAL_CTRL_13_8 ro — Reserved
  [7:0] CMN_PLL0_VCOCAL_CTRL_7_0 ro — VCO calibration code: This is the calibration code that was determined by the VCO calibration process.
0x104 CMN_PLL0_VCOCAL_OVRD__CMN_PLL0_VCOCAL_TCTRL reset 0x4 — PLL 0 VCO calibration timer control register
  [31] CMN_PLL0_VCOCAL_OVRD_15 rw — VCO calibration code override enable: Activating (1'b1) this bit allows the VCO code determined during the automatic VCO calibration process to be overridden by the value driven by the VCO calibration code override value field in this register.
  [30:24] CMN_PLL0_VCOCAL_OVRD_14_8 ro — Reserved
  [23:16] CMN_PLL0_VCOCAL_OVRD_7_0 rw — VCO calibration code override value: This field is used to override the VCO code determined during the automatic VCO calibration process.
  [15:3] CMN_PLL0_VCOCAL_TCTRL_15_3 ro — Reserved
  [2:0] CMN_PLL0_VCOCAL_TCTRL_2_0 rw — VCO calibration initial time scale control: This field specifies the calibration start time scaling factor applied to the VCO calibration when running the initial step size for the calibration code if not set to 1.
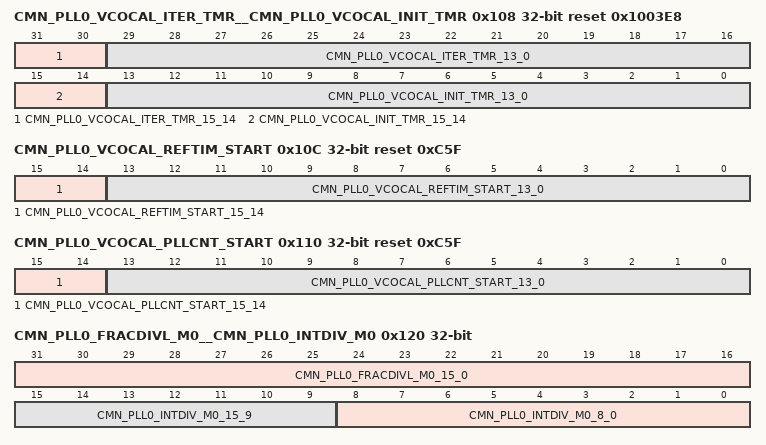
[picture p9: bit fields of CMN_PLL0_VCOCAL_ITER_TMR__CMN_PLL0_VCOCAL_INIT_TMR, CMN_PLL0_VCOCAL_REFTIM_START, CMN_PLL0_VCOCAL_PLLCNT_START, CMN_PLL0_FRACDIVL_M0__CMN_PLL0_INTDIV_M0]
0x108 CMN_PLL0_VCOCAL_ITER_TMR__CMN_PLL0_VCOCAL_INIT_TMR reset 0x1003E8 — PLL 0 VCO calibration initialization timer register
  [31:30] CMN_PLL0_VCOCAL_ITER_TMR_15_14 ro — Reserved
  [29:16] CMN_PLL0_VCOCAL_ITER_TMR_13_0 rw — Iteration wait timer value: This is the number of clocks to wait between when a calibration code is driven to the analog, and when the clock rates are measured.
  [15:14] CMN_PLL0_VCOCAL_INIT_TMR_15_14 ro — Reserved
  [13:0] CMN_PLL0_VCOCAL_INIT_TMR_13_0 rw — Initialization wait timer value: This is the number of clocks to wait between when the analog VCO calibration circuits are enabled, and when the first calibration code is driven to the analog.
0x10C CMN_PLL0_VCOCAL_REFTIM_START reset 0xC5F — PLL 0 VCO calibration reference clock timer start value register
  [15:14] CMN_PLL0_VCOCAL_REFTIM_START_15_14 ro — Reserved
  [13:0] CMN_PLL0_VCOCAL_REFTIM_START_13_0 rw — PLL VCO calibration reference clock timer start value : This is the value that is loaded into the reference clock timer as the starting point for that timer, when running VCO calibration.
0x110 CMN_PLL0_VCOCAL_PLLCNT_START reset 0xC5F — PLL 0 VCO calibration PLL clock counter start value register
  [15:14] CMN_PLL0_VCOCAL_PLLCNT_START_15_14 ro — Reserved
  [13:0] CMN_PLL0_VCOCAL_PLLCNT_START_13_0 rw — PLL VCO calibration PLL clock counter start value : This is the value that is loaded into the PLL clock counter as the starting point for that counter, when running VCO calibration.
0x120 CMN_PLL0_FRACDIVL_M0__CMN_PLL0_INTDIV_M0 — PLL 0 feedback divider integer register mode 0
  [31:16] CMN_PLL0_FRACDIVL_M0_15_0 rw — pll_fb_div_fractional: Value of the pll_fb_div_fractional[15:0] signal.
  [15:9] CMN_PLL0_INTDIV_M0_15_9 ro — Reserved
  [8:0] CMN_PLL0_INTDIV_M0_8_0 rw — pll_fb_div_integer value: Value of the pll_fb_div_integer signal.
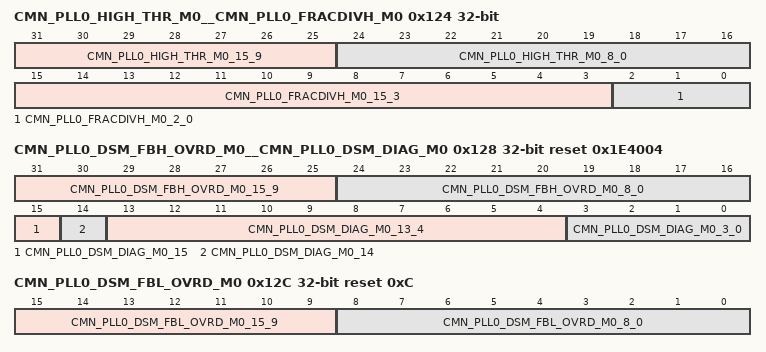
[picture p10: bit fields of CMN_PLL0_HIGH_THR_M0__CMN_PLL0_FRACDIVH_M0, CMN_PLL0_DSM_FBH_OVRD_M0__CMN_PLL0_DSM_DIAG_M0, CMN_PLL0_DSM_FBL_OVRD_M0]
0x124 CMN_PLL0_HIGH_THR_M0__CMN_PLL0_FRACDIVH_M0 — PLL 0 feedback divider fractional high register mode 0
  [31:25] CMN_PLL0_HIGH_THR_M0_15_9 ro — Reserved
  [24:16] CMN_PLL0_HIGH_THR_M0_8_0 rw — pll_fb_div_high_theshold: Value of the pll_fb_div_high_threshold signal.
  [15:3] CMN_PLL0_FRACDIVH_M0_15_3 ro — Reserved
  [2:0] CMN_PLL0_FRACDIVH_M0_2_0 rw — pll_fb_div_fractional: Value of the pll_fb_div_fractional[18:16] signal.
0x128 CMN_PLL0_DSM_FBH_OVRD_M0__CMN_PLL0_DSM_DIAG_M0 reset 0x1E4004 — PLL 0 delta sigma modulator diagnostics register mode 0
  [31:25] CMN_PLL0_DSM_FBH_OVRD_M0_15_9 ro — Reserved
  [24:16] CMN_PLL0_DSM_FBH_OVRD_M0_8_0 rw — PLL feedback divider high override value : When enabled by the PLL feedback divider override enable bit in the PLL 0 delta sigma modulator diagnostics register mode 0 on page 102, the value in this field will be used to override the value on the cmnda_pll0_fb_div_high signal.
  [15] CMN_PLL0_DSM_DIAG_M0_15 rw — Delta sigma bypass enable: When set to 1'b1, the delta sigma modulator will be bypassed, and the output will be the value specified for the internal pll_fb_div_integer signal.
  [14] CMN_PLL0_DSM_DIAG_M0_14 rw — PLL feedback divider override enable : When active (1'b1), the feedback divider low and high override values in the PLL 0 delta sigma modulator feedback divider value high override register mode 0 on page 102 and PLL 0 delta sigma modulator feedback divider value low override register mode 0 on page 102 registers will be used to override the feedback divider values driven to the analog.
  [13:4] CMN_PLL0_DSM_DIAG_M0_13_4 ro — Reserved
  [3:0] CMN_PLL0_DSM_DIAG_M0_3_0 rw — PLL feedback divider latency adjustment: This signal specifies a value to be subtracted from the feedback divider settings before they are output on the cmnda_pll0_fb_div_high and cmnda_pll0_fb_div_low signals.
0x12C CMN_PLL0_DSM_FBL_OVRD_M0 reset 0xC — PLL 0 delta sigma modulator feedback divider value low override register mode 0
  [15:9] CMN_PLL0_DSM_FBL_OVRD_M0_15_9 ro — Reserved
  [8:0] CMN_PLL0_DSM_FBL_OVRD_M0_8_0 rw — PLL feedback divider low override value : When enabled by the PLL feedback divider override enable bit in the PLL 0 delta sigma modulator diagnostics register mode 0 on page 102, the value in this field will be used to override the value on the cmnda_pll0_fb_div_low signal.
